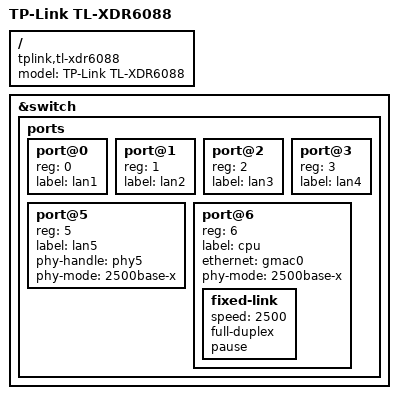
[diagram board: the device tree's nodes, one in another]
// SPDX-License-Identifier: GPL-2.0-or-later OR MIT

/dts-v1/;
#include "mt7986a-tl-xdr-common.dtsi"

/ {
	model = "TP-Link TL-XDR6088";
	compatible = "tplink,tl-xdr6088", "mediatek,mt7986a";
};

&switch {
	ports {
		#address-cells = <1>;
		#size-cells = <0>;

		port@0 {
			reg = <0>;
			label = "lan1";
		};

		port@1 {
			reg = <1>;
			label = "lan2";
		};

		port@2 {
			reg = <2>;
			label = "lan3";
		};

		port@3 {
			reg = <3>;
			label = "lan4";
		};

		port@5 {
			reg = <5>;
			label = "lan5";
			phy-handle = <&phy5>;
			phy-mode = "2500base-x";
		};

		port@6 {
			reg = <6>;
			label = "cpu";
			ethernet = <&gmac0>;
			phy-mode = "2500base-x";

			fixed-link {
				speed = <2500>;
				full-duplex;
				pause;
			};
		};
	};
};
